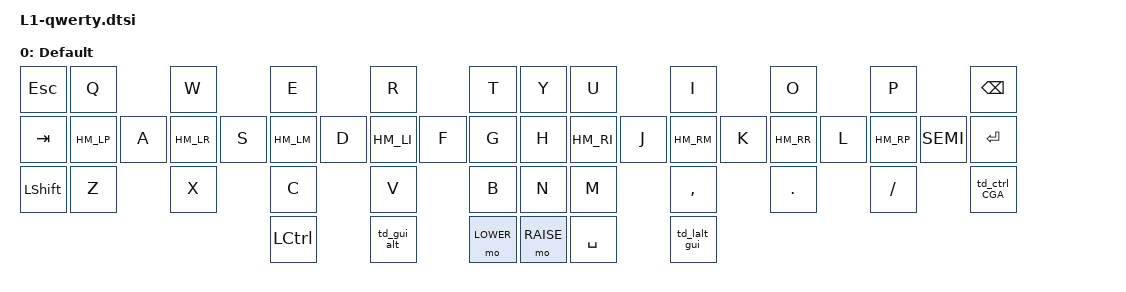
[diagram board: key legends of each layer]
/**
 *
 */

/ {
  keymap {
    compatible = "zmk,keymap";

	default_layer {
		label = "Default";
		bindings = <
// ╭───────────────┬───────────────┬───────────────┬───────────────┬───────────────┬───────────────╮   ╭───────────────┬───────────────┬───────────────┬───────────────┬───────────────┬───────────────╮
    &kp ESC         &kp Q           &kp W           &kp E           &kp R           &kp T               &kp Y           &kp U           &kp I           &kp O           &kp P         	&kp BSPC
// ├───────────────├───────────────┼───────────────┼───────────────┼───────────────┼───────────────┤   ├───────────────├───────────────┼───────────────┼───────────────┼───────────────┼───────────────┤
    &kp TAB			HM_LP A      	HM_LR S       	HM_LM D      	HM_LI F      	&kp G               &kp H           HM_RI J     	HM_RM K   		HM_RR L      	HM_RP SEMI		&kp ENTER
// ├───────────────├───────────────┼───────────────┼───────────────┼───────────────┼───────────────┤   ├───────────────├───────────────┼───────────────┼───────────────┼───────────────┼───────────────┤
    &kp LSHFT 		&kp Z     		&kp X      		&kp C      		&kp V       	&kp B               &kp N           &kp M       	&kp COMMA  		&kp DOT   		&kp FSLH  		&td_ctrl_CGA
// ╰───────────────┴───────────────┴───────────────┼───────────────┼───────────────┼───────────────┤   ├───────────────├───────────────┼───────────────┼───────────────┴───────────────┴───────────────╯
                                                    &kp LCTRL       &td_gui_alt		&mo LOWER			&mo RAISE		&kp SPACE 		&td_lalt_gui
//                                                 ╰───────────────┴───────────────┴───────────────╯   ╰───────────────┴───────────────┴───────────────╯
			>;
		};
    };
};
